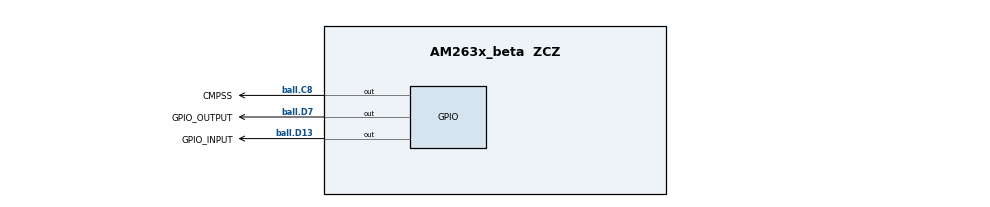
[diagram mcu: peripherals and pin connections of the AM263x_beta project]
/**
 * @cliArgs --device "AM263x_beta" --package "ZCZ" --part "AM263x" --context "r5fss0-0" --product "MCU_PLUS_SDK@07.03.01"
 * @versions {"tool":"1.13.0+2553"}
 */

/**
 * Import the modules used in this configuration.
 */
const cmpss      = scripting.addModule("/drivers/cmpss/cmpss", {}, false);
const cmpss1     = cmpss.addInstance();
const gpio       = scripting.addModule("/drivers/gpio/gpio", {}, false);
const gpio1      = gpio.addInstance();
const gpio2      = gpio.addInstance();
const gpio3      = gpio.addInstance();
const uart       = scripting.addModule("/drivers/uart/uart", {}, false);
const uart1      = uart.addInstance();
const clock      = scripting.addModule("/kernel/dpl/clock");
const debug_log  = scripting.addModule("/kernel/dpl/debug_log");
const mpu_armv7  = scripting.addModule("/kernel/dpl/mpu_armv7", {}, false);
const mpu_armv71 = mpu_armv7.addInstance();
const mpu_armv72 = mpu_armv7.addInstance();
const mpu_armv73 = mpu_armv7.addInstance();
const mpu_armv74 = mpu_armv7.addInstance();

/**
 * Write custom configuration values to the imported modules.
 */
cmpss1.$name = "CONFIG_CMPSS0";

gpio1.$name                = "GPIO_INPUT";
gpio1.GPIO.gpioPin.$assign = "ball.D13";

gpio2.pinDir               = "OUTPUT";
gpio2.$name                = "GPIO_OUTPUT";
gpio2.GPIO.gpioPin.$assign = "ball.D7";

gpio3.$name                = "CMPSS";
gpio3.GPIO.gpioPin.$assign = "ball.C8";

uart1.$name            = "TESTER_UART";
uart1.UART.$assign     = "UART3";
uart1.UART.RXD.$assign = "SPI0_CS0";
uart1.UART.TXD.$assign = "SPI0_CLK";

debug_log.enableUartLog            = true;
debug_log.enableCssLog             = false;
debug_log.uartLog.$name            = "CONFIG_UART0";
debug_log.uartLog.UART.RXD.$assign = "UART0_RXD";
debug_log.uartLog.UART.TXD.$assign = "UART0_TXD";

mpu_armv71.$name             = "CONFIG_MPU_REGION0";
mpu_armv71.size              = 31;
mpu_armv71.attributes        = "Device";
mpu_armv71.accessPermissions = "Supervisor RD+WR, User RD";
mpu_armv71.allowExecute      = false;

mpu_armv72.$name             = "CONFIG_MPU_REGION1";
mpu_armv72.size              = 15;
mpu_armv72.accessPermissions = "Supervisor RD+WR, User RD";

mpu_armv73.$name             = "CONFIG_MPU_REGION2";
mpu_armv73.baseAddr          = 0x80000;
mpu_armv73.size              = 15;
mpu_armv73.accessPermissions = "Supervisor RD+WR, User RD";

mpu_armv74.$name             = "CONFIG_MPU_REGION3";
mpu_armv74.accessPermissions = "Supervisor RD+WR, User RD";
mpu_armv74.baseAddr          = 0x70000000;
mpu_armv74.size              = 21;

/**
 * Pinmux solution for unlocked pins/peripherals. This ensures that minor changes to the automatic solver in a future
 * version of the tool will not impact the pinmux you originally saw.  These lines can be completely deleted in order to
 * re-solve from scratch.
 */
gpio1.GPIO.$suggestSolution             = "GPIO0";
gpio2.GPIO.$suggestSolution             = "GPIO0";
gpio3.GPIO.$suggestSolution             = "GPIO0";
debug_log.uartLog.UART.$suggestSolution = "UART0";
